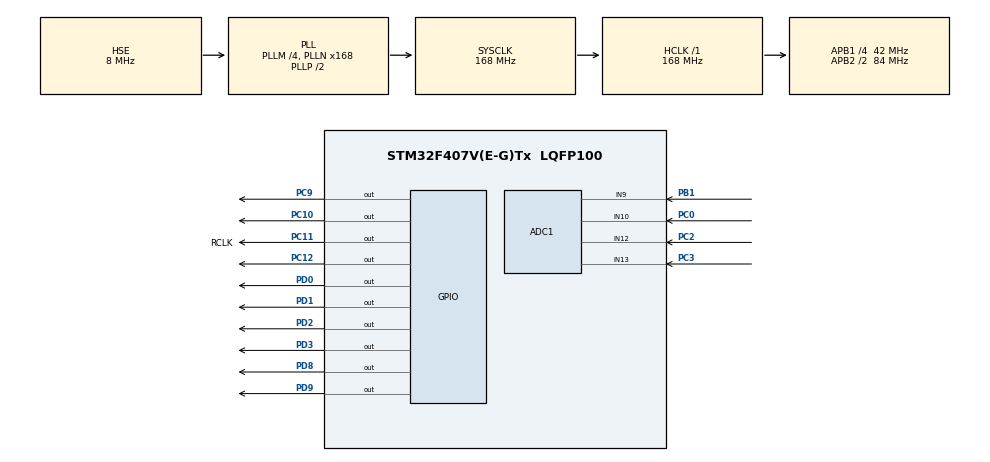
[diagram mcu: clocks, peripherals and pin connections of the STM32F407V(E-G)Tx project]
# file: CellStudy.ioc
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ADC1.Channel-0\#ChannelRegularConversion=ADC_CHANNEL_10
ADC1.Channel-1\#ChannelRegularConversion=ADC_CHANNEL_12
ADC1.Channel-2\#ChannelRegularConversion=ADC_CHANNEL_13
ADC1.Channel-3\#ChannelRegularConversion=ADC_CHANNEL_9
ADC1.ContinuousConvMode=ENABLE
ADC1.DMAContinuousRequests=ENABLE
ADC1.NbrOfConversion=4
ADC1.NbrOfConversionFlag=1
ADC1.Rank-0\#ChannelRegularConversion=1
ADC1.Rank-1\#ChannelRegularConversion=2
ADC1.Rank-2\#ChannelRegularConversion=3
ADC1.Rank-3\#ChannelRegularConversion=4
ADC1.SamplingTime-0\#ChannelRegularConversion=ADC_SAMPLETIME_56CYCLES
ADC1.SamplingTime-1\#ChannelRegularConversion=ADC_SAMPLETIME_56CYCLES
ADC1.SamplingTime-2\#ChannelRegularConversion=ADC_SAMPLETIME_56CYCLES
ADC1.SamplingTime-3\#ChannelRegularConversion=ADC_SAMPLETIME_56CYCLES
ADC1.ScanConvMode=ENABLE
ADC1.master=1
Dma.ADC1.0.Direction=DMA_PERIPH_TO_MEMORY
Dma.ADC1.0.FIFOMode=DMA_FIFOMODE_DISABLE
Dma.ADC1.0.Instance=DMA2_Stream0
Dma.ADC1.0.MemDataAlignment=DMA_MDATAALIGN_HALFWORD
Dma.ADC1.0.MemInc=DMA_MINC_ENABLE
Dma.ADC1.0.Mode=DMA_CIRCULAR
Dma.ADC1.0.PeriphDataAlignment=DMA_PDATAALIGN_HALFWORD
Dma.ADC1.0.PeriphInc=DMA_PINC_DISABLE
Dma.ADC1.0.Priority=DMA_PRIORITY_LOW
Dma.Request0=ADC1
Mcu.Family=STM32F4
Mcu.Name=STM32F407V(E-G)Tx
Mcu.Package=LQFP100
NVIC.DMA2_Stream0_IRQn=true\:0\:0\:false\:false\:true\:false\:true\:true
NVIC.PriorityGroup=NVIC_PRIORITYGROUP_4
PB1.Signal=ADCx_IN9
PC0.Signal=ADCx_IN10
PC10.Signal=GPIO_Output
PC11.GPIO_Label=RCLK
PC11.Signal=GPIO_Output
PC12.Signal=GPIO_Output
PC2.Signal=ADCx_IN12
PC3.Signal=ADCx_IN13
PC9.Signal=GPIO_Output
PD0.Signal=GPIO_Output
PD1.Signal=GPIO_Output
PD2.Signal=GPIO_Output
PD3.Signal=GPIO_Output
PD8.Signal=GPIO_Output
PD9.Signal=GPIO_Output
PH0-OSC_IN.Mode=HSE-External-Oscillator
PH0-OSC_IN.Signal=RCC_OSC_IN
PH1-OSC_OUT.Mode=HSE-External-Oscillator
PH1-OSC_OUT.Signal=RCC_OSC_OUT
ProjectManager.HeapSize=0x200
ProjectManager.StackSize=0x400
ProjectManager.TargetToolchain=STM32CubeIDE
RCC.48MHZClocksFreq_Value=84000000
RCC.AHBFreq_Value=168000000
RCC.APB1CLKDivider=RCC_HCLK_DIV4
RCC.APB1Freq_Value=42000000
RCC.APB1TimFreq_Value=84000000
RCC.APB2CLKDivider=RCC_HCLK_DIV2
RCC.APB2Freq_Value=84000000
RCC.APB2TimFreq_Value=168000000
RCC.CortexFreq_Value=168000000
RCC.HCLKFreq_Value=168000000
RCC.HSE_VALUE=8000000
RCC.HSI_VALUE=16000000
RCC.LSE_VALUE=32768
RCC.PLLM=4
RCC.PLLN=168
RCC.PLLSourceVirtual=RCC_PLLSOURCE_HSE
RCC.SYSCLKFreq_VALUE=168000000
RCC.SYSCLKSource=RCC_SYSCLKSOURCE_PLLCLK
RCC.VCOOutputFreq_Value=336000000
SH.ADCx_IN10.0=ADC1_IN10,IN10
SH.ADCx_IN12.0=ADC1_IN12,IN12
SH.ADCx_IN13.0=ADC1_IN13,IN13
SH.ADCx_IN9.0=ADC1_IN9,IN9
board=custom

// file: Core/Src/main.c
/* USER CODE BEGIN Header */
/**
  ******************************************************************************
  * @file           : main.c
  * @brief          : Main program body
  ******************************************************************************
  * @attention
  *
  * Copyright (c) 2024 STMicroelectronics.
  * All rights reserved.
  *
  * This software is licensed under terms that can be found in the LICENSE file
  * in the root directory of this software component.
  * If no LICENSE file comes with this software, it is provided AS-IS.
  *
  ******************************************************************************
  */
/* USER CODE END Header */
#include "main.h"
#include "adc.h"
#include "dma.h"
#include "gpio.h"

/* USER CODE BEGIN Includes */
#include "7SEG.h"
#include "levelmeter.h"

/* USER CODE END Includes */

/* USER CODE BEGIN PV */
//uint8_t rx3_data;
/* USER CODE END PV */

void SystemClock_Config(void);

int main(void)
{
  /* USER CODE BEGIN 1 */
	volatile uint16_t adcval[4];
	uint16_t caladc,digit10;

	uint8_t ledStates[10] = {0};
	uint16_t buffer = 0;
	uint8_t data = 0b01010101;
  /* USER CODE END 1 */

  /* MCU Configuration--------------------------------------------------------*/

  /* Reset of all peripherals, Initializes the Flash interface and the Systick. */
  HAL_Init();

  /* Configure the system clock */
  SystemClock_Config();

  /* Initialize all configured peripherals */
  MX_GPIO_Init();
  MX_DMA_Init();
  MX_ADC1_Init();
  /* USER CODE BEGIN 2 */
  //HAL_UART_Receive_IT(&huart3, &rx3_data, 1);
  HAL_ADC_Start_DMA(&hadc1, adcval, 4);
  _7SEG_GPIO_Init();
  /* USER CODE END 2 */

  /* Infinite loop */
  /* USER CODE BEGIN WHILE */

  while (1)
  {
	  caladc = adcval[0];
	  digit10 = caladc / 410;
	  //digit1 = caladc % 10;

//	  led_refresh(led_status(adcval[0]/410,ledStates));
//	  buffer = HAL_GPIO_ReadPin(GPIOC, GPIO_PIN_8);
      displayLevel(calculateLevel(caladc));

	  _7SEG_SetNumber(DGT1,digit10, OFF);
	  _7SEG_SetNumber(DGT2,buffer, ON);

	  //HAL_Delay(1000);

    /* USER CODE END WHILE */

  }
}

void SystemClock_Config(void)
{
  RCC_OscInitTypeDef RCC_OscInitStruct = {0};
  RCC_ClkInitTypeDef RCC_ClkInitStruct = {0};

  /** Configure the main internal regulator output voltage
  */
  __HAL_RCC_PWR_CLK_ENABLE();
  __HAL_PWR_VOLTAGESCALING_CONFIG(PWR_REGULATOR_VOLTAGE_SCALE1);

  /** Initializes the RCC Oscillators according to the specified parameters
  * in the RCC_OscInitTypeDef structure.
  */
  RCC_OscInitStruct.OscillatorType = RCC_OSCILLATORTYPE_HSE;
  RCC_OscInitStruct.HSEState = RCC_HSE_ON;
  RCC_OscInitStruct.PLL.PLLState = RCC_PLL_ON;
  RCC_OscInitStruct.PLL.PLLSource = RCC_PLLSOURCE_HSE;
  RCC_OscInitStruct.PLL.PLLM = 4;
  RCC_OscInitStruct.PLL.PLLN = 168;
  RCC_OscInitStruct.PLL.PLLP = RCC_PLLP_DIV2;
  RCC_OscInitStruct.PLL.PLLQ = 4;
  if (HAL_RCC_OscConfig(&RCC_OscInitStruct) != HAL_OK)
  {
    Error_Handler();
  }

  /** Initializes the CPU, AHB and APB buses clocks
  */
  RCC_ClkInitStruct.ClockType = RCC_CLOCKTYPE_HCLK|RCC_CLOCKTYPE_SYSCLK
                              |RCC_CLOCKTYPE_PCLK1|RCC_CLOCKTYPE_PCLK2;
  RCC_ClkInitStruct.SYSCLKSource = RCC_SYSCLKSOURCE_PLLCLK;
  RCC_ClkInitStruct.AHBCLKDivider = RCC_SYSCLK_DIV1;
  RCC_ClkInitStruct.APB1CLKDivider = RCC_HCLK_DIV4;
  RCC_ClkInitStruct.APB2CLKDivider = RCC_HCLK_DIV2;

  if (HAL_RCC_ClockConfig(&RCC_ClkInitStruct, FLASH_LATENCY_5) != HAL_OK)
  {
    Error_Handler();
  }
}

void Error_Handler(void)
{
  __disable_irq();
  while (1)
  {
  }
}
